# AT91SAM9G10 register map
Vendor: Atmel; File version: 20130207
CPU: 
Registers are 32-bit, read-write, no defined reset value unless marked. A register's access mark holds for its fields unless they carry their own. Offsets are from the block's base; [hi:lo] are bit positions.

## TWI — Two-wire Interface
Base 0xFFFAC000; register names take the prefix TWI_
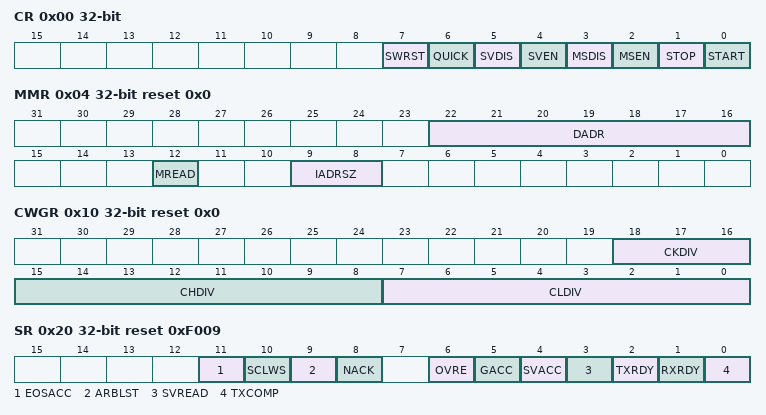
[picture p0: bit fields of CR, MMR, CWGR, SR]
0x00 CR wo — Control Register
  [7] SWRST — Software Reset
  [6] QUICK — SMBUS Quick Command
  [5] SVDIS — TWI Slave Mode Disabled
  [4] SVEN — TWI Slave Mode Enabled
  [3] MSDIS — TWI Master Mode Disabled
  [2] MSEN — TWI Master Mode Enabled
  [1] STOP — Send a STOP Condition
  [0] START — Send a START Condition
0x04 MMR reset 0x0 — Master Mode Register
  [22:16] DADR — Device Address
  [12] MREAD — Master Read Direction
  [9:8] IADRSZ — Internal Device Address Size
0x08 SMR reset 0x0 — Slave Mode Register
  [22:16] SADR — Slave Address
0x0C IADR reset 0x0 — Internal Address Register
  [23:0] IADR — Internal Address
0x10 CWGR reset 0x0 — Clock Waveform Generator Register
  [18:16] CKDIV — Clock Divider
  [15:8] CHDIV — Clock High Divider
  [7:0] CLDIV — Clock Low Divider
0x20 SR ro reset 0xF009 — Status Register
  [11] EOSACC — End Of Slave Access (clear on read)
  [10] SCLWS — Clock Wait State (automatically set / reset)
  [9] ARBLST — Arbitration Lost (clear on read)
  [8] NACK — Not Acknowledged (clear on read)
  [6] OVRE — Overrun Error (clear on read)
  [5] GACC — General Call Access (clear on read)
  [4] SVACC — Slave Access (automatically set / reset)
  [3] SVREAD — Slave Read (automatically set / reset)
  [2] TXRDY — Transmit Holding Register Ready (automatically set / reset)
  [1] RXRDY — Receive Holding Register Ready (automatically set / reset)
  [0] TXCOMP — Transmission Completed (automatically set / reset)
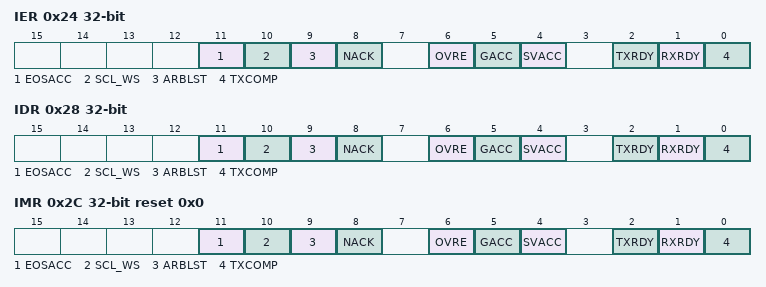
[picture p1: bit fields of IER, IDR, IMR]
0x24 IER wo — Interrupt Enable Register
  [11] EOSACC — End Of Slave Access Interrupt Enable
  [10] SCL_WS — Clock Wait State Interrupt Enable
  [9] ARBLST — Arbitration Lost Interrupt Enable
  [8] NACK — Not Acknowledge Interrupt Enable
  [6] OVRE — Overrun Error Interrupt Enable
  [5] GACC — General Call Access Interrupt Enable
  [4] SVACC — Slave Access Interrupt Enable
  [2] TXRDY — Transmit Holding Register Ready Interrupt Enable
  [1] RXRDY — Receive Holding Register Ready Interrupt Enable
  [0] TXCOMP — Transmission Completed Interrupt Enable
0x28 IDR wo — Interrupt Disable Register
  [11] EOSACC — End Of Slave Access Interrupt Disable
  [10] SCL_WS — Clock Wait State Interrupt Disable
  [9] ARBLST — Arbitration Lost Interrupt Disable
  [8] NACK — Not Acknowledge Interrupt Disable
  [6] OVRE — Overrun Error Interrupt Disable
  [5] GACC — General Call Access Interrupt Disable
  [4] SVACC — Slave Access Interrupt Disable
  [2] TXRDY — Transmit Holding Register Ready Interrupt Disable
  [1] RXRDY — Receive Holding Register Ready Interrupt Disable
  [0] TXCOMP — Transmission Completed Interrupt Disable
0x2C IMR ro reset 0x0 — Interrupt Mask Register
  [11] EOSACC — End Of Slave Access Interrupt Mask
  [10] SCL_WS — Clock Wait State Interrupt Mask
  [9] ARBLST — Arbitration Lost Interrupt Mask
  [8] NACK — Not Acknowledge Interrupt Mask
  [6] OVRE — Overrun Error Interrupt Mask
  [5] GACC — General Call Access Interrupt Mask
  [4] SVACC — Slave Access Interrupt Mask
  [2] TXRDY — Transmit Holding Register Ready Interrupt Mask
  [1] RXRDY — Receive Holding Register Ready Interrupt Mask
  [0] TXCOMP — Transmission Completed Interrupt Mask
0x30 RHR ro reset 0x0 — Receive Holding Register
  [7:0] RXDATA — Master or Slave Receive Holding Data
0x34 THR wo reset 0x0 — Transmit Holding Register
  [7:0] TXDATA — Master or Slave Transmit Holding Data

## SDRAMC — SDRAM Controller
Base 0xFFFFEA00; register names take the prefix SDRAMC_
0x00 MR reset 0x0 — SDRAMC Mode Register
  [2:0] MODE — SDRAMC Command Mode
0x04 TR reset 0x0 — SDRAMC Refresh Timer Register
  [11:0] COUNT — SDRAMC Refresh Timer Count
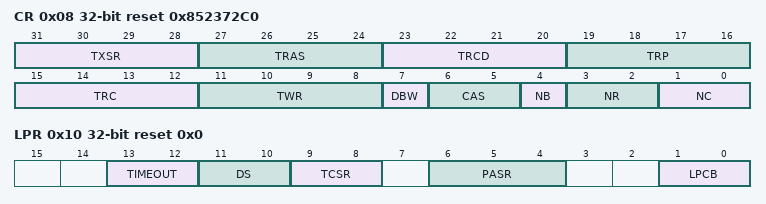
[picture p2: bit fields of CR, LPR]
0x08 CR reset 0x852372C0 — SDRAMC Configuration Register
  [31:28] TXSR — Exit Self Refresh to Active Delay
  [27:24] TRAS — Active to Precharge Delay
  [23:20] TRCD — Row to Column Delay
  [19:16] TRP — Row Precharge Delay
  [15:12] TRC — Row Cycle Delay
  [11:8] TWR — Write Recovery Delay
  [7] DBW — Data Bus Width
  [6:5] CAS — CAS Latency
  [4] NB — Number of Banks
  [3:2] NR — Number of Row Bits
  [1:0] NC — Number of Column Bits
0x10 LPR reset 0x0 — SDRAMC Low Power Register
  [13:12] TIMEOUT — Time to define when low-power mode is enabled
  [11:10] DS — Drive Strength (only for low-power SDRAM)
  [9:8] TCSR — Temperature Compensated Self-Refresh (only for low-power SDRAM)
  [6:4] PASR — Partial Array Self-refresh (only for low-power SDRAM)
  [1:0] LPCB — Low-power Configuration Bits
0x14 IER wo — SDRAMC Interrupt Enable Register
  [0] RES — Refresh Error Status
0x18 IDR wo — SDRAMC Interrupt Disable Register
  [0] RES — Refresh Error Status
0x1C IMR ro reset 0x0 — SDRAMC Interrupt Mask Register
  [0] RES — Refresh Error Status
0x20 ISR ro reset 0x0 — SDRAMC Interrupt Status Register
  [0] RES — Refresh Error Status
0x24 MDR ro reset 0x0 — SDRAMC Memory Device Register
  [1:0] MD — Memory Device Type
